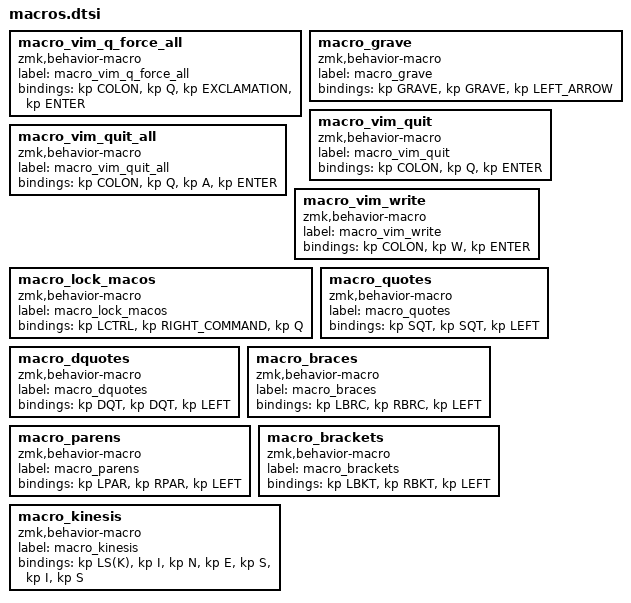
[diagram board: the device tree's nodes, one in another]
macro_vim_q_force_all: macro_vim_q_force_all{
compatible = "zmk,behavior-macro";
label = "macro_vim_q_force_all";
#binding-cells = <0>;
bindings = <&kp COLON>, <&kp Q>, <&kp EXCLAMATION>, <&kp ENTER>;
};
macro_grave: macro_grave{
compatible = "zmk,behavior-macro";
label = "macro_grave";
#binding-cells = <0>;
bindings = <&kp GRAVE>, <&kp GRAVE>, <&kp LEFT_ARROW>;
};
macro_vim_quit: macro_vim_quit{
compatible = "zmk,behavior-macro";
label = "macro_vim_quit";
#binding-cells = <0>;
bindings = <&kp COLON>, <&kp Q>, <&kp ENTER>;
};
macro_vim_quit_all: macro_vim_quit_all{
compatible = "zmk,behavior-macro";
label = "macro_vim_quit_all";
#binding-cells = <0>;
bindings = <&kp COLON>, <&kp Q>, <&kp A>, <&kp ENTER>;
};
macro_vim_write: macro_vim_write{
compatible = "zmk,behavior-macro";
label = "macro_vim_write";
#binding-cells = <0>;
bindings = <&kp COLON>, <&kp W>, <&kp ENTER>;
};
macro_lock_macos: macro_lock_macos{
compatible = "zmk,behavior-macro";
label = "macro_lock_macos";
#binding-cells = <0>;
bindings = <&kp LCTRL>, <&kp RIGHT_COMMAND>, <&kp Q>;
};
macro_quotes: macro_quotes{
compatible = "zmk,behavior-macro";
label = "macro_quotes";
#binding-cells = <0>;
bindings = <&kp SQT>, <&kp SQT>, <&kp LEFT>;
};
macro_dquotes: macro_dquotes{
compatible = "zmk,behavior-macro";
label = "macro_dquotes";
#binding-cells = <0>;
bindings = <&kp DQT>, <&kp DQT>, <&kp LEFT>;
};
macro_braces: macro_braces{
compatible = "zmk,behavior-macro";
label = "macro_braces";
#binding-cells = <0>;
bindings = <&kp LBRC>, <&kp RBRC>, <&kp LEFT>;
};
macro_parens: macro_parens{
compatible = "zmk,behavior-macro";
label = "macro_parens";
#binding-cells = <0>;
bindings = <&kp LPAR>, <&kp RPAR>, <&kp LEFT>;
};
macro_brackets: macro_brackets{
compatible = "zmk,behavior-macro";
label = "macro_brackets";
#binding-cells = <0>;
bindings = <&kp LBKT>, <&kp RBKT>, <&kp LEFT>;
};
macro_kinesis: macro_kinesis{
compatible = "zmk,behavior-macro";
label = "macro_kinesis";
#binding-cells = <0>;
bindings = <&kp LS(K)>, <&kp I>, <&kp N>, <&kp E>, <&kp S>, <&kp I>, <&kp S>;
};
